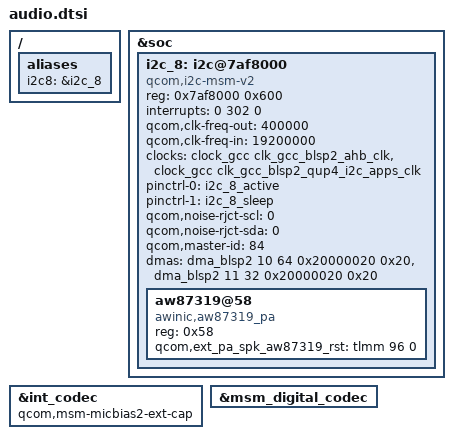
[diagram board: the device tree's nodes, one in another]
/ {
	aliases {
		i2c8 = &i2c_8;
	};
};

&soc {
	i2c_8: i2c@7af8000 { /* BLSP2 QUP3 */
		compatible = "qcom,i2c-msm-v2";
		#address-cells = <1>;
		#size-cells = <0>;
		reg-names = "qup_phys_addr";
		reg = <0x7af8000 0x600>;
		interrupt-names = "qup_irq";
		interrupts = <0 302 0>;
		qcom,clk-freq-out = <400000>;
		qcom,clk-freq-in  = <19200000>;
		clock-names = "iface_clk", "core_clk";
		clocks = <&clock_gcc clk_gcc_blsp2_ahb_clk>,
			<&clock_gcc clk_gcc_blsp2_qup4_i2c_apps_clk>;

		pinctrl-names = "i2c_active", "i2c_sleep";
		pinctrl-0 = <&i2c_8_active>;
		pinctrl-1 = <&i2c_8_sleep>;
		qcom,noise-rjct-scl = <0>;
		qcom,noise-rjct-sda = <0>;
		qcom,master-id = <84>;
		dmas = <&dma_blsp2 10 64 0x20000020 0x20>,
			<&dma_blsp2 11 32 0x20000020 0x20>;
		dma-names = "tx", "rx";
        status = "disabled";
	};
};

&i2c_8 {
	status = "okay";
    aw87319@58{ /*AW87319 PA*/
		compatible = "awinic,aw87319_pa";
		reg = <0x58>;
		qcom,ext_pa_spk_aw87319_rst = <&tlmm 96 0>;
        status = "okay";
	};
};

&int_codec {
	qcom,msm-micbias2-ext-cap;
};

&msm_digital_codec {
	status = "ok";
};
